# UPD70F3508 register map
Vendor: Renesas; Series: V850E2/Px4; File version: 1.0
CPU: other r0p0, little endian, no MPU, FPU, 4 interrupt priority bits
Registers are 8-bit, read-write, reset 0x0 unless marked. A register's access mark holds for its fields unless they carry their own. Offsets are from the block's base; [hi:lo] are bit positions.

## OSTM0 — OS Timer 0 (OSTM0)
Base 0xFF800020
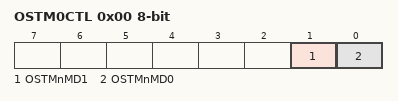
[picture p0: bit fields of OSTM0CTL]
0x00 OSTM0CTL — OSTM0 Control Register
  [1] OSTMnMD1 — Operating mode: 0=interval timer mode, 1=free-running comparison mode
  [0] OSTMnMD0 — Start-of-counting interrupt: 0=disabled, 1=enabled
0x7FBFE0 OSTM0CMP 32-bit — OSTM0 Compare Register (down-counter start value or comparison value)
  [31:0] OSTMnCMP — Compare/start value [31:0]
0x7FBFE4 OSTM0CNT 32-bit ro — OSTM0 Counter Register (current 32-bit counter value, read-only)
  [31:0] OSTMnCNT — 32-bit counter value
0x7FBFE8 OSTM0TO — OSTM0 Output Register (OSTMnTTOUT output level)
  [0] OSTMnTO — OSTMnTTOUT output level: 0=low, 1=high (write valid only in software control mode)
0x7FBFEC OSTM0TOE — OSTM0 Output Enable Register (OSTMnTTOUT output mode)
  [0] OSTMnTOE — Output mode: 0=software control, 1=timer-output toggling on OSTMnTINT
0x7FBFF0 OSTM0TE ro — OSTM0 Count Enable Status Register (counter enabled/disabled status)
  [0] OSTMnTE — Counter enable status: 0=disabled, 1=enabled
0x7FBFF4 OSTM0TS wo — OSTM0 Count Start Trigger Register (write 1 to start counter)
  [0] OSTMnTS — Start trigger: 1=start counter (always reads 0)
0x7FBFF8 OSTM0TT wo — OSTM0 Count Stop Trigger Register (write 1 to stop counter)
  [0] OSTMnTT — Stop trigger: 1=stop counter and clear OSTMnTE (always reads 0)

## OSTM1 — OS Timer 1 (OSTM1)
Base 0xFF801020
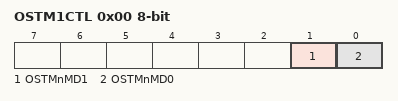
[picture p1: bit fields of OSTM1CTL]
0x00 OSTM1CTL — OSTM1 Control Register
  [1] OSTMnMD1 — Operating mode: 0=interval timer mode, 1=free-running comparison mode
  [0] OSTMnMD0 — Start-of-counting interrupt: 0=disabled, 1=enabled
0x7FB0E0 OSTM1CMP 32-bit — OSTM1 Compare Register (down-counter start value or comparison value)
  [31:0] OSTMnCMP — Compare/start value [31:0]
0x7FB0E4 OSTM1CNT 32-bit ro — OSTM1 Counter Register (current 32-bit counter value, read-only)
  [31:0] OSTMnCNT — 32-bit counter value
0x7FB0E8 OSTM1TO — OSTM1 Output Register (OSTMnTTOUT output level)
  [0] OSTMnTO — OSTMnTTOUT output level: 0=low, 1=high (write valid only in software control mode)
0x7FB0EC OSTM1TOE — OSTM1 Output Enable Register (OSTMnTTOUT output mode)
  [0] OSTMnTOE — Output mode: 0=software control, 1=timer-output toggling on OSTMnTINT
0x7FB0F0 OSTM1TE ro — OSTM1 Count Enable Status Register (counter enabled/disabled status)
  [0] OSTMnTE — Counter enable status: 0=disabled, 1=enabled
0x7FB0F4 OSTM1TS wo — OSTM1 Count Start Trigger Register (write 1 to start counter)
  [0] OSTMnTS — Start trigger: 1=start counter (always reads 0)
0x7FB0F8 OSTM1TT wo — OSTM1 Count Stop Trigger Register (write 1 to stop counter)
  [0] OSTMnTT — Stop trigger: 1=stop counter and clear OSTMnTE (always reads 0)

## CLMA0 — Clock Monitor A, instance 0 — monitors main oscillator
Base 0xFF802000
0x00 CLMA0CTL0 — CLMA0 Control Register 0 — enables/disables clock monitor (write-protected)
  [0] CLMA0CLME — Clock monitor enable: 0=disabled, 1=enabled (can only be cleared by reset)
0x04 CLMA0CTL1 — CLMA0 Control Register 1 — selects output signal on under-frequency detection
  [0] CLMA0OSEL — Output select: 0=reset request CLMAnRES, 1=error interrupt CLMAnTI + CLMAnTERR
0x08 CLMA0CMPL 16-bit reset 0x1 — CLMA0 Compare Register L — lower frequency threshold [11:0]
  [11:0] CLMA0CMPL11_0 — Lower threshold (min valid CLMAnTMON edge count in 16 sampling cycles); minimum 0001H
0x0C CLMA0CMPH 16-bit reset 0x3FF — CLMA0 Compare Register H — upper frequency threshold [11:0]
  [11:0] CLMA0CMPH11_0 — Upper threshold (max valid CLMAnTMON edge count in 16 sampling cycles); minimum = CMPL+0003H
0x10 CLMA0PCMD wo — CLMA0 Protection Command Register — write A5H before write sequence to CTL0
  [7:0] CLMA0REG7_0 — Protection command byte; write A5H to unlock CTL0 write sequence
0x14 CLMA0PS ro — CLMA0 Protection Status Register — indicates success/failure of CTL0 write
  [0] CLMA0PRERR — Protection write error: 0=write succeeded, 1=write failed

## CLMA1 — Clock Monitor A, instance 1 — monitors internal system clock
Base 0xFF803000
Registers as CLMA0 (with CLMA0 read as CLMA1).

## CLMA2 — Clock Monitor A, instance 2 — monitors internal oscillator
Base 0xFF804000
Registers as CLMA0 (with CLMA0 read as CLMA2); these are added or differ:
0x04 CLMA2CTL1 — CLMA2 Control Register 1 — selects output signal on under-frequency detection
  [0] CLMA2OSEL — Output select: 0=reset request CLMAnRES, 1=error interrupt CLMAnTI + CLMAnTERR (note: SGA detects internal OSC stop regardless)
